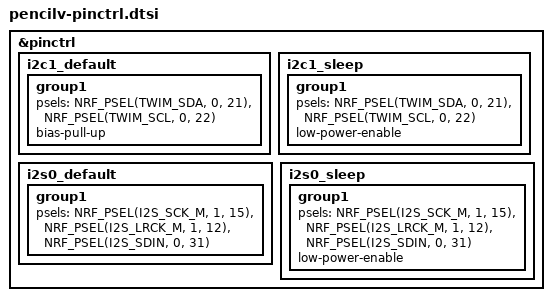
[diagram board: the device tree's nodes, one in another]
/* SPDX-License-Identifier: Apache-2.0 */

&pinctrl {
    i2c1_default: i2c1_default {
        group1 {
            psels = <NRF_PSEL(TWIM_SDA, 0, 21)>,
                    <NRF_PSEL(TWIM_SCL, 0, 22)>;
            bias-pull-up;
        };
    };

    i2c1_sleep: i2c1_sleep {
        group1 {
            psels = <NRF_PSEL(TWIM_SDA, 0, 21)>,
                    <NRF_PSEL(TWIM_SCL, 0, 22)>;
            low-power-enable;
        };
    };

    i2s0_default: i2s0_default {
        group1 {
            psels = <NRF_PSEL(I2S_SCK_M, 1, 15)>,
                    <NRF_PSEL(I2S_LRCK_M, 1, 12)>,
                    <NRF_PSEL(I2S_SDIN, 0, 31)>;
        };
    };

    i2s0_sleep: i2s0_sleep {
        group1 {
            psels = <NRF_PSEL(I2S_SCK_M, 1, 15)>,
                    <NRF_PSEL(I2S_LRCK_M, 1, 12)>,
                    <NRF_PSEL(I2S_SDIN, 0, 31)>;
            low-power-enable;
        };
    };
};
